# R7FA8D1BH register map
Vendor: Renesas; Series: RA8; File version: 1.2
CPU: CM85 r0p0, little endian, MPU, FPU, VTOR, 4 interrupt priority bits
Registers are 32-bit, read-write, reset 0x0 unless marked. A register's access mark holds for its fields unless they carry their own. Offsets are from the block's base; [hi:lo] are bit positions.

## AGT0 — Low Power Asynchronous General purpose Timer 0
Base 0x40221000
Same registers: AGT1 0x40221100, AGT0_NS 0x50221000, AGT1_NS 0x50221100
0x00 AGT 16-bit reset 0xFFFF — AGT Counter Register
  [15:0] AGT — 16bit counter and reload registerNOTE : When 1 is written to the TSTOP bit in the AGTCRn register, the 16-bit counter is forcibly stopped and set to FFFFH.
0x02 AGTCMA 16-bit reset 0xFFFF — AGT Compare Match A Register
  [15:0] AGTCMA — AGT Compare Match A RegisterNOTE : When 1 is written to the TSTOP bit in the AGTCRn register, set to FFFFH
0x04 AGTCMB 16-bit reset 0xFFFF — AGT Compare Match B Register
  [15:0] AGTCMB — AGT Compare Match B RegisterNOTE : When 1 is written to the TSTOP bit in the AGTCR register, set to FFFFH
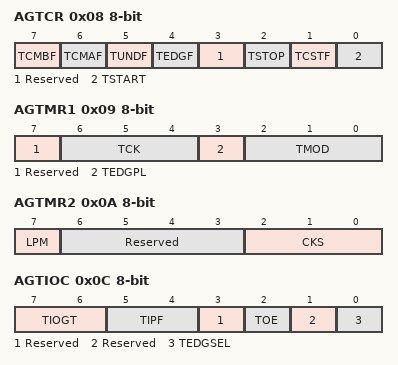
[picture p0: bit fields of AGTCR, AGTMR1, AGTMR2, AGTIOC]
0x08 AGTCR 8-bit — AGT Control Register
  [7] TCMBF write-0-clears read-modifies — AGT compare match B flag
    0=No Match; 1=Match
  [6] TCMAF write-0-clears read-modifies — AGT compare match A flag
    0=No Match; 1=Match
  [5] TUNDF write-0-clears read-modifies — AGT underflow flag
    0=No underflow; 1=Underflow
  [4] TEDGF write-0-clears read-modifies — Active edge judgement flag
    0=No active edge received; 1=Active edge received
  [3] Reserved — This bit is read as 0. The write value should be 0.
  [2] TSTOP wo — AGT count forced stop
    0=no effect; 1=The count is forcibly stopped
  [1] TCSTF ro — AGT count status flag
    0=Count stops; 1=Count starts
  [0] TSTART — AGT count start
    0=Count stops; 1=Count starts
0x09 AGTMR1 8-bit — AGT Mode Register 1
  [7] Reserved — This bit is read as 0. The write value should be 0.
  [6:4] TCK — AGT count source select
    0=PCLKB; 1=PCLKB/8; 3=PCLKB/2; 4=Divided clock LOCO specified by AGTMR2.CKS bit; 5=Underflow event signal from AGT; 6=Divided clock fSUB specified by AGTMR2.CKS bit; other=others (Setting prohibited)
  [3] TEDGPL — AGTIO edge polarity select
    0=One edge; 1=Both edges
  [2:0] TMOD — AGT operating mode select
    0=Timer mode; 1=Pulse output mode; 2=Event counter mode; 3=Pulse width measurement mode; 4=Pulse period measurement mode; other=others (Setting prohibited)
0x0A AGTMR2 8-bit — AGT Mode Register 2
  [7] LPM — AGT Low Power Mode
    0=Normal mode; 1=Low Power mode
  [6:3] Reserved — These bits are read as 0000. The write value should be 0000.
  [2:0] CKS — fsub/LOCO count source clock frequency division ratio select
    0=1/1; 1=1/2; 2=1/4; 3=1/8; 4=1/16; 5=1/32; 6=1/64; 7=1/128
0x0C AGTIOC 8-bit — AGT I/O Control Register
  [7:6] TIOGT — AGTIO count control
    0=Event is always counted; 1=Event is counted during polarity period specified for AGTEE; other=others (Setting prohibited)
  [5:4] TIPF — AGTIO input filter select
    0=No filter; 1=Filter sampled at PCLKB; 2=Filter sampled at PCLKB/8; 3=Filter sampled at PCLKB/32
  [3] Reserved — This bit is read as 0. The write value should be 0.
  [2] TOE — AGTO output enable
    0=AGTO output disabled (port); 1=AGTO output enabled
  [1] Reserved — This bit is read as 0. The write value should be 0.
  [0] TEDGSEL — I/O polarity switchFunction varies depending on the operating mode.
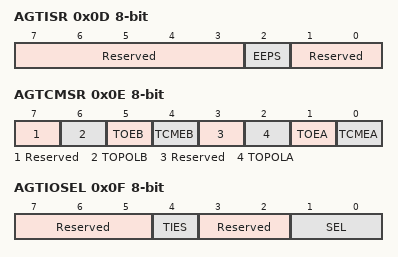
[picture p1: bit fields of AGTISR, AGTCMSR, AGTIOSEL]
0x0D AGTISR 8-bit — AGT Event Pin Select Register
  [7:3] Reserved — These bits are read as 00000. The write value should be 00000.
  [2] EEPS — AGTEE polarty selection
    0=An event is counted during the low-level period; 1=An event is counted during the high-level period
  [1:0] Reserved — These bits are read as 00. The write value should be 00.
0x0E AGTCMSR 8-bit — AGT Compare Match Function Select Register
  [7] Reserved — This bit is read as 0. The write value should be 0.
  [6] TOPOLB — AGTOB polarity select
    0=AGTOB Output is started at low; 1=AGTOB Output is started at high
  [5] TOEB — AGTOB output enable
    0=AGTOB output disabled (port); 1=AGTOB output enabled
  [4] TCMEB — Compare match B register enable
    0=Disable compare match B register; 1=Enable compare match B register
  [3] Reserved — This bit is read as 0. The write value should be 0.
  [2] TOPOLA — AGTOA polarity select
    0=AGTOA Output is started at low; 1=AGTOA Output is started at high
  [1] TOEA — AGTOA output enable
    0=AGTOA output disabled (port); 1=AGTOA output enabled
  [0] TCMEA — Compare match A register enable
    0=Disable compare match A register; 1=Enable compare match A register
0x0F AGTIOSEL 8-bit — AGT Pin Select Register
  [7:5] Reserved — These bits are read as 000. The write value should be 000.
  [4] TIES — AGTIO input enable
    0=external event input disable during software standby mode; 1=external event input enable during software standby mode
  [3:2] Reserved — These bits are read as 00. The write value should be 00.
  [1:0] SEL — AGTIO pin select
    0=AGTIO_A can not be used as AGTIO input pin in deep software standby mode; 1=Setting prohibited; 2=AGTIO_B can be used as AGTIO input pin in deep software standby mode. AGTIO_B is input only. It is not possible to output.; 3=AGTIO_C can be used as AGTIO input pin in deep software standby mode. AGTIO_C is input only. It is not possible to output.
